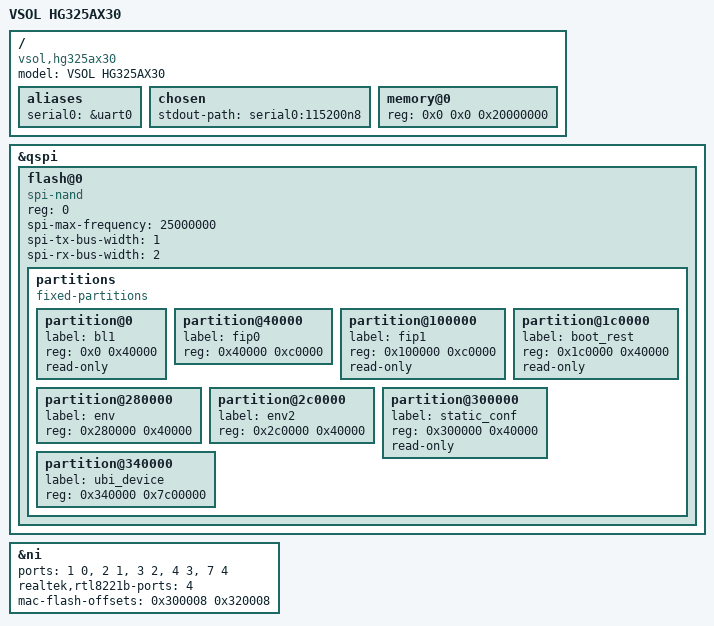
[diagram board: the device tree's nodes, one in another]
// SPDX-License-Identifier: GPL-2.0+
/*
 * VSOL HG325AX30 (Realtek RTL9607DQ "Taurus"), U-Boot control device tree.
 */

/dts-v1/;

#include "rtl9607dq.dtsi"

/ {
	model = "VSOL HG325AX30";
	compatible = "vsol,hg325ax30", "realtek,rtl9607dq", "realtek,taurus";

	aliases {
		serial0 = &uart0;
	};

	chosen {
		stdout-path = "serial0:115200n8";
	};

	memory@0 {
		device_type = "memory";
		reg = <0x0 0x0 0x20000000>;
	};
};

&qspi {
	flash@0 {
		compatible = "spi-nand";
		reg = <0>;
		spi-max-frequency = <25000000>;
		spi-tx-bus-width = <1>;
		spi-rx-bus-width = <2>;

		partitions {
			compatible = "fixed-partitions";
			#address-cells = <1>;
			#size-cells = <1>;

			/*
			 * The boot partition, split along its GPT: only the
			 * active FIP (fip0) is writable, so an upgrade can
			 * never touch the standby copy BL2 falls back to.
			 */
			partition@0 {
				label = "bl1";
				reg = <0x0 0x40000>;
				read-only;
			};

			partition@40000 {
				label = "fip0";
				reg = <0x40000 0xc0000>;
			};

			partition@100000 {
				label = "fip1";
				reg = <0x100000 0xc0000>;
				read-only;
			};

			partition@1c0000 {
				label = "boot_rest";
				reg = <0x1c0000 0x40000>;
				read-only;
			};

			partition@280000 {
				label = "env";
				reg = <0x280000 0x40000>;
			};

			partition@2c0000 {
				label = "env2";
				reg = <0x2c0000 0x40000>;
			};

			partition@300000 {
				label = "static_conf";
				reg = <0x300000 0x40000>;
				read-only;
			};

			partition@340000 {
				label = "ubi_device";
				reg = <0x340000 0x7c00000>;
			};
		};
	};
};

&ni {
	/*
	 * <MDIO address, NI port>: lan1 to lan3, the unused fourth GbE PHY,
	 * and the RTL8221B of lan4 behind the SerDes
	 */
	ports = <1 0>, <2 1>, <3 2>, <4 3>, <7 4>;
	realtek,rtl8221b-ports = <4>;
	/* the two copies of the MAC address in static_conf (0x300000, 0x320000) */
	mac-flash-offsets = <0x300008 0x320008>;
};
